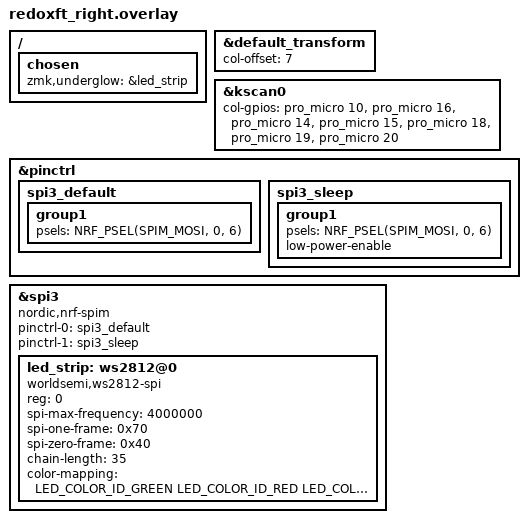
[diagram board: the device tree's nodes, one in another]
#include "redoxft.dtsi"
#include <dt-bindings/led/led.h>

&default_transform {
    col-offset = <7>;
};

&kscan0 {
    col-gpios
        = <&pro_micro 10 GPIO_ACTIVE_HIGH>
        , <&pro_micro 16 GPIO_ACTIVE_HIGH>
        , <&pro_micro 14 GPIO_ACTIVE_HIGH>
        , <&pro_micro 15 GPIO_ACTIVE_HIGH>
        , <&pro_micro 18 GPIO_ACTIVE_HIGH>
        , <&pro_micro 19 GPIO_ACTIVE_HIGH>
        , <&pro_micro 20 GPIO_ACTIVE_HIGH>
        ;
};

/* WS2812 — 35 per-key LEDs, data na D1/TX (P0.06) */
&pinctrl {
    spi3_default: spi3_default {
        group1 {
            psels = <NRF_PSEL(SPIM_MOSI, 0, 6)>;
        };
    };
    spi3_sleep: spi3_sleep {
        group1 {
            psels = <NRF_PSEL(SPIM_MOSI, 0, 6)>;
            low-power-enable;
        };
    };
};

&spi3 {
    compatible = "nordic,nrf-spim";
    status = "okay";
    pinctrl-0 = <&spi3_default>;
    pinctrl-1 = <&spi3_sleep>;
    pinctrl-names = "default", "sleep";

    led_strip: ws2812@0 {
        compatible = "worldsemi,ws2812-spi";
        reg = <0>;
        spi-max-frequency = <4000000>;
        spi-one-frame = <0x70>;
        spi-zero-frame = <0x40>;
        chain-length = <35>;
        color-mapping = <LED_COLOR_ID_GREEN
                         LED_COLOR_ID_RED
                         LED_COLOR_ID_BLUE>;
    };
};

/ {
    chosen {
        zmk,underglow = &led_strip;
    };
};
